# D1H register map
Vendor: Allwinner; File version: 1.0
Registers are 32-bit, read-write, reset 0x0 unless marked. A register's access mark holds for its fields unless they carry their own. Offsets are from the block's base; [hi:lo] are bit positions; {n}, {i} and the like mark numbered series; 'fields as' and 'values as' point back to an identical list.

## TWI[{n}] — Two Wire Interface
Base 0x02502000; array of 4, step 0x400
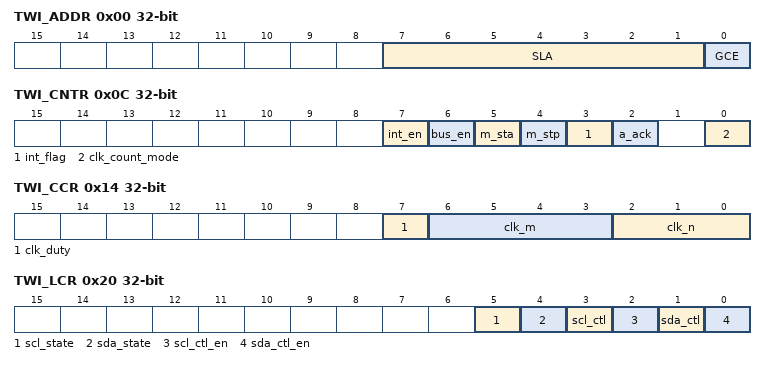
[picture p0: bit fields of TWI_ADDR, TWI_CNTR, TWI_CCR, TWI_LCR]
0x00 TWI_ADDR — TWI Slave Address Register
  [7:1] SLA — Slave Address
  [0] GCE
    0=disable; 1=enable
0x04 TWI_XADDR — TWI Extended Slave Address Register
  [7:0] SLAX — Extend Slave Address . SLAX[7:0]
0x08 TWI_DATA — TWI Data Byte Register
  [7:0] data — Data byte transmitted or received
0x0C TWI_CNTR — TWI Control Register
  [7] int_en — Interrupt Enable
    0=low (The interrupt line always low); 1=high (The interrupt line will go high when INT_FLAG is set)
  [6] bus_en — TWI Bus Enable
    0=ignored; 1=respond
  [5] m_sta — Master Mode Start
  [4] m_stp — Master Mode Stop
  [3] int_flag — Interrupt Flag
  [2] a_ack — Assert Acknowledge
  [0] clk_count_mode
    0=oscl (scl clock high period count on oscl); 1=iscl (scl clock high period count on iscl)
0x10 TWI_STAT ro — TWI Status Register
  [7:0] sta
    0=be (Bus error); 8=sct (START condition transmitted); 16=rsct (Repeated START condition transmitted); 24=awbt_ar (Address + Write bit transmitted, ACK received); 32=awbt_anr (Address + Write bit transmitted, ACK not received); 40=dbtm_ar (Data byte transmitted in master mode, ACK received); 48=dbtm_anr (Data byte transmitted in master mode, ACK not received); 56=al_a_db (Arbitration lost in address or data byte); 64=arbt_ar (Address + Read bit transmitted, ACK received); 72=arbt_anr (Address + Read bit transmitted, ACK not received); 80=dbrm_at (Data byte received in master mode, ACK transmitted); 88=dbrm_ant (Data byte received in master mode, not ACK transmitted); 96=sawr_at (Slave address + Write bit received, ACK transmitted); 104=al_am_sawr_at (Arbitration lost in the address as master, slave address + Write bit received, ACK transmitted); 112=gcar_at (General Call address received, ACK transmitted); 120=al_am_gcar_at (Arbitration lost in the address as master, General Call address received, ACK transmitted); 128=dbr_sar_at (Data byte received after slave address received, ACK transmitted); 136=dbr_sar_ant (Data byte received after slave address received, not ACK transmitted); 144=dbr_gcr_at (Data byte received after General Call received, ACK transmitted); 152=dbr_gcr_ant (Data byte received after General Call received, not ACK transmitted); 160=srscrs (STOP or repeated START condition received in slave mode); 168=sarr_at (Slave address + Read bit received, ACK transmitted); 176=al_am_sarr_at (Arbitration lost in the address as master, slave address + Read bit received, ACK transmitted); 184=dbts_ar (Data byte transmitted in slave mode, ACK received); 192=dbts_anr (Data byte transmitted in slave mode, ACK not received); 200=lbts_ar (The Last byte transmitted in slave mode, ACK received); 208=sawt_ar (Second Address byte + Write bit transmitted, ACK received); 216=sawt_anr (Second Address byte + Write bit transmitted, ACK not received); 248=nrsi (No relevant status information, INT_FLAG=0)
0x14 TWI_CCR — TWI Clock Control Register
  [7] clk_duty — Setting duty cycle of clock as master
    0=P50 (50%); 1=P40 (40%)
  [6:3] clk_m
  [2:0] clk_n
0x18 TWI_SRST — TWI Software Reset Register
  [0] soft_rst — Soft Reset
0x1C TWI_EFR — TWI Enhance Feature Register
  [1:0] dbn — Data Byte Number Follow Read Command Control
    0=B0 (No data byte can be written after the read command); 1=B1 (1-byte data can be written after the read command); 2=B2 (2-byte data can be written after the read command); 3=B3 (3-byte data can be written after the read command)
0x20 TWI_LCR — TWI Line Control Register
  [5] scl_state ro — Current State of TWI_SCL
    0=low; 1=high
  [4] sda_state ro — Current State of TWI_SDA
    0=low; 1=high
  [3] scl_ctl — TWI_SCL Line State Control Bit
    0=low; 1=high
  [2] scl_ctl_en — TWI_SCL Line State Control Enable
    0=disable; 1=enable
  [1] sda_ctl — TWI_SDA Line State Control Bit
    0=low; 1=high
  [0] sda_ctl_en — TWI_SDA Line State Control Enable
    0=disable; 1=enable
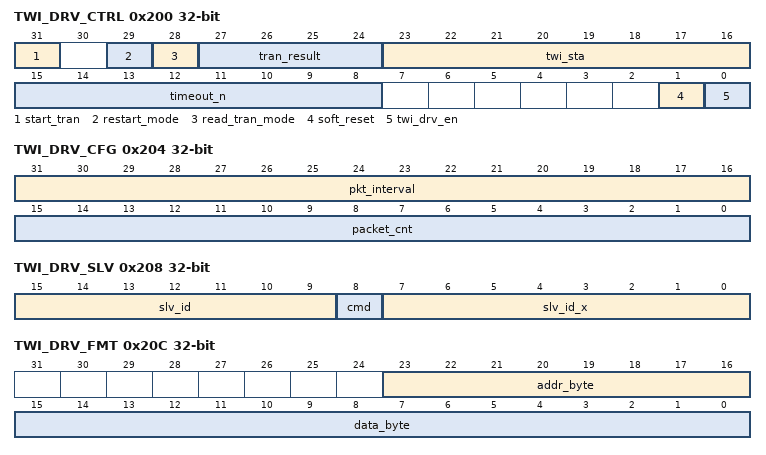
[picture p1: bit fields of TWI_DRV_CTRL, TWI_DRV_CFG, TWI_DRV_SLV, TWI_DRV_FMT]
0x200 TWI_DRV_CTRL — TWI_DRV Control Register
  [31] start_tran — Start transmission
    0=idle; 1=start
  [29] restart_mode
    0=restart; 1=stop_restart
  [28] read_tran_mode — Read transition mode
    0=send; 1=not_send
  [27:24] tran_result — Transition result
    0=ok; 1=fail
  [23:16] twi_sta ro — TWI status
    0=be (bus error); 8=sct (START condition transmitted); 16=rsct (Repeated START condition transmitted); 24=awbt_ar (Address + Write bit transmitted, ACK received); 32=awbt_anr (Address + Write bit transmitted, ACK not received); 40=dbtm_ar (Data byte transmitted in master mode, ACK received); 48=dbtm_anr (Data byte transmitted in master mode, ACK not received); 56=al_a_db (Arbitration lost in address or data byte); 64=arbt_ar (Address + Read bit transmitted, ACK received); 72=arbt_anr (Address + Read bit transmitted, ACK not received); 80=dbrm_ar (Data byte received in master mode, ACK received); 88=dbrm_anr (Data byte received in master mode, ACK not received); 1=t_s9sc (Timeout when sending the 9th SCL clock)
  [15:8] timeout_n — Timeout number
  [1] soft_reset — Software reset
    0=normal; 1=reset
  [0] twi_drv_en
    0=disable; 1=enable
0x204 TWI_DRV_CFG — TWI_DRV Transmission Configuration Register
  [31:16] pkt_interval, [15:0] packet_cnt
0x208 TWI_DRV_SLV — TWI_DRV Slave ID Register
  [15:9] slv_id — Slave device ID
  [8] cmd — R/W operation to slave device
    0=write; 1=read
  [7:0] slv_id_x — SLAX[7:0]
0x20C TWI_DRV_FMT — TWI_DRV Packet Format Register
  [23:16] addr_byte, [15:0] data_byte
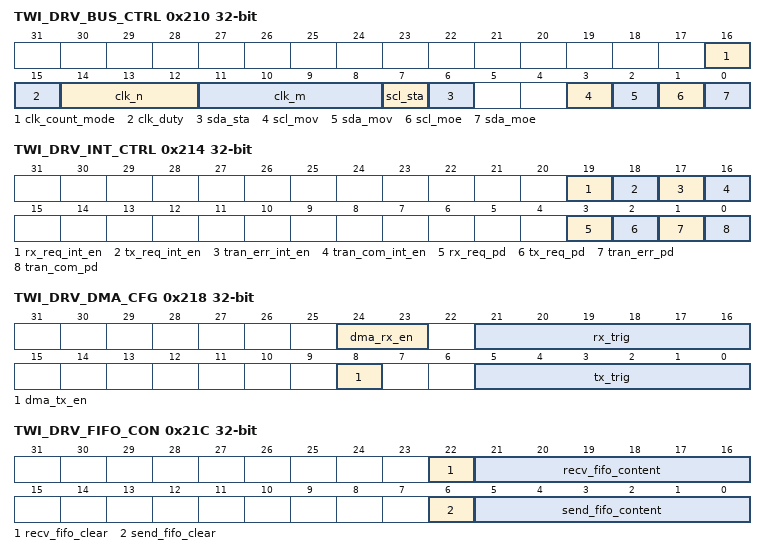
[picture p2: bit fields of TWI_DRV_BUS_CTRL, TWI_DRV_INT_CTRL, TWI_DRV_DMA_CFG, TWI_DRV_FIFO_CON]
0x210 TWI_DRV_BUS_CTRL — TWI_DRV Bus Control Register
  [16] clk_count_mode wo
    values as TWI_CNTR.clk_count_mode
  [15] clk_duty — Setting duty cycle of clock as master
    0=P50 (50%); 1=P40 (40%)
  [14:12] clk_n
  [11:8] clk_m
  [7] scl_sta ro — SCL current status
  [6] sda_sta ro — SDA current status
  [3] scl_mov — SCL manual output value
  [2] sda_mov — SDA manual output value
  [1] scl_moe — SCL manual output enable
  [0] sda_moe — SDA manual output enable
0x214 TWI_DRV_INT_CTRL — TWI_DRV Interrupt Control Register
  [19] rx_req_int_en, [18] tx_req_int_en, [17] tran_err_int_en, [16] tran_com_int_en, [3] rx_req_pd, [2] tx_req_pd, [1] tran_err_pd, [0] tran_com_pd
0x218 TWI_DRV_DMA_CFG — TWI_DRV DMA Configure Register
  [24:23] dma_rx_en, [21:16] rx_trig, [8] dma_tx_en, [5:0] tx_trig
0x21C TWI_DRV_FIFO_CON — TWI_DRV FIFO Content Register
  [22] recv_fifo_clear, [21:16] recv_fifo_content, [6] send_fifo_clear, [5:0] send_fifo_content
0x300 TWI_DRV_SEND_FIFO_ACC wo — TWI_DRV Send Data FIFO Access Register
  [7:0] send_data_fifo
0x304 TWI_DRV_RECV_FIFO_ACC ro — TWI_DRV Receive Data FIFO Access Register
  [7:0] recv_data_fifo
